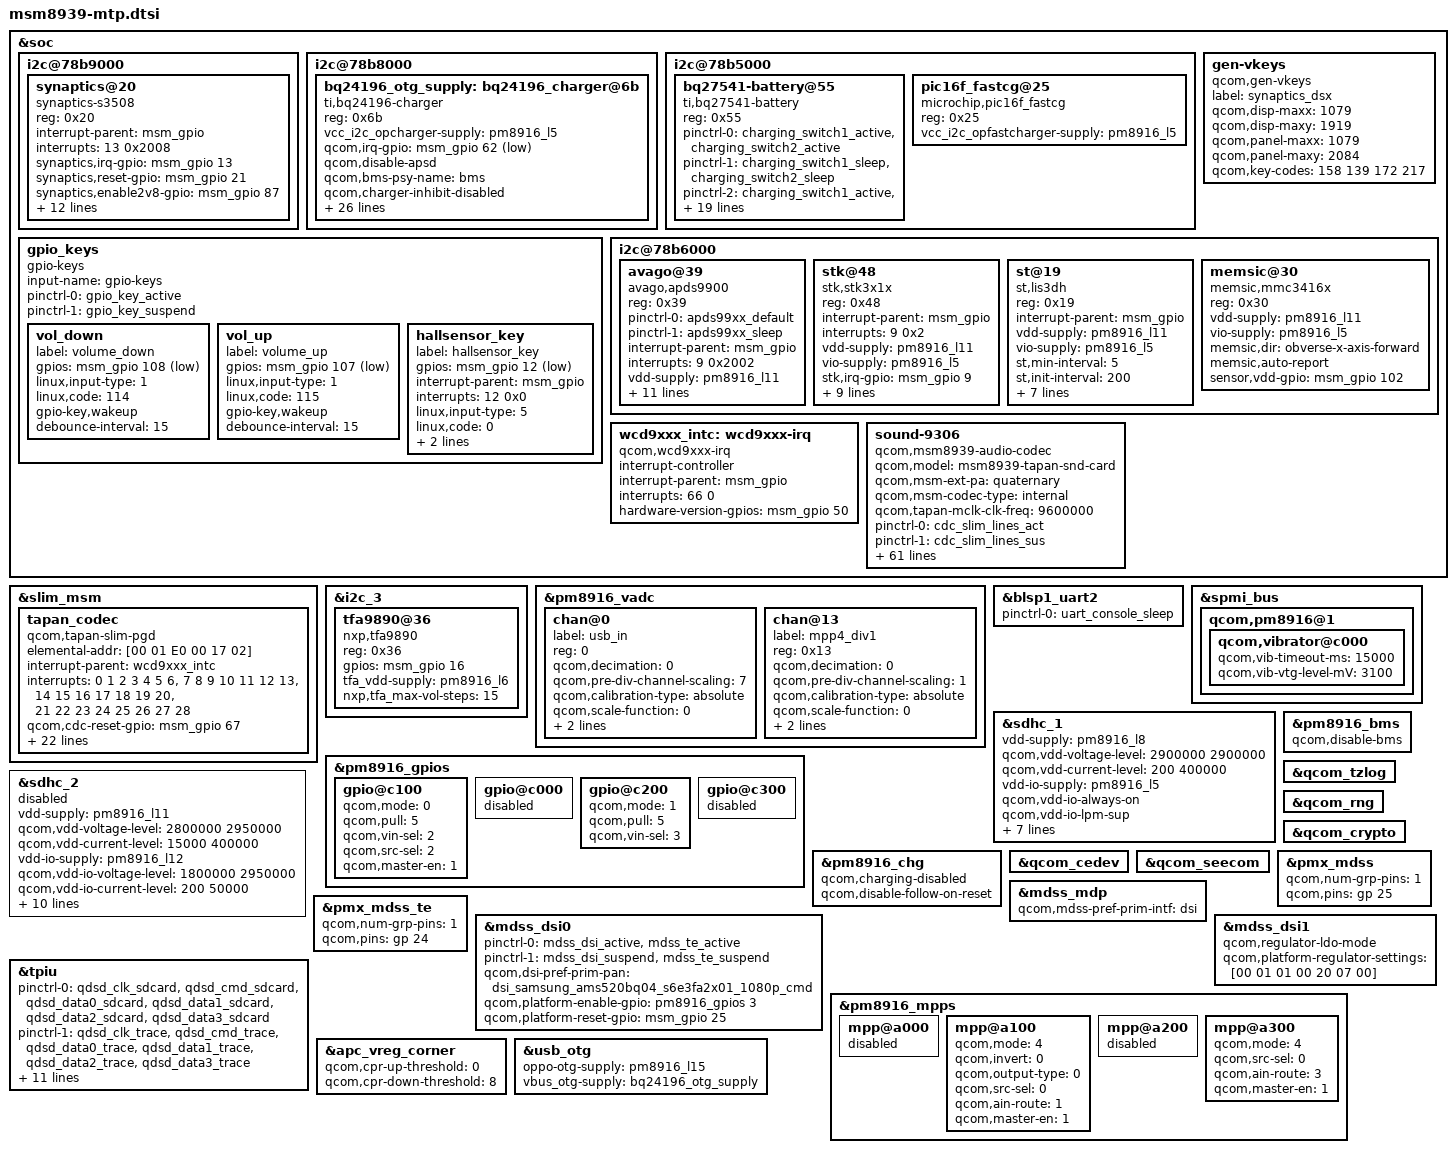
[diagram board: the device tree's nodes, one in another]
/* Copyright (c) 2014-2015, The Linux Foundation. All rights reserved.
 *
 * This program is free software; you can redistribute it and/or modify
 * it under the terms of the GNU General Public License version 2 and
 * only version 2 as published by the Free Software Foundation.
 *
 * This program is distributed in the hope that it will be useful,
 * but WITHOUT ANY WARRANTY; without even the implied warranty of
 * MERCHANTABILITY or FITNESS FOR A PARTICULAR PURPOSE.  See the
 * GNU General Public License for more details.
 */

#include "msm8939-pinctrl.dtsi"
#include "msm8939-camera-sensor-mtp.dtsi"

&soc {
	i2c@78b9000 { /* BLSP1 QUP5 */
		synaptics@20 {/*tong.han add for TP */
			compatible = "synaptics-s3508";
			reg = <0x20>;
			interrupt-parent = <&msm_gpio>;
			interrupts = <13 0x2008>;
			synaptics,irq-gpio = <&msm_gpio 13 0x2008>;
			synaptics,reset-gpio = <&msm_gpio 21 0x00>;
			synaptics,enable2v8-gpio = <&msm_gpio 87 0x00>;
			pinctrl-names = "default";
			pinctrl-0 = <&ts_int_active>;

			synaptics,max-num-support = <10>;
			synaptics,max-x-point = <10>;
			synaptics,button-map= <200 200 2021>;//width-height-y.position
			synaptics,tx-rx-num = <20 31>;
			synaptics,display-coords = <1080 1920>;
			synaptics,panel-coords = <0 0 1079 2084>;//max_x,max_y of display area--Not include virtual keys!
			synaptics,max-y-point = <1745>;
			vcc_i2c_1v8-supply = <&pm8916_l5>;
			/* huqiao@EXP.BasicDrv.Basic add for 15062 TP */
			//synaptics,glove-mode-enabled;
			synaptics,i2c-pull-up;
			synaptics,power-down;
			synaptics,disable-gpios;
		};
	};


	/*nanwei.Deng@bsp.drv add for charger start*/
	i2c@78b8000 { /* BLSP1 QUP4 =i2c4*/
		//Add bq24196_otg_supply for vbus_otg-supply by qiujianfeng
		bq24196_otg_supply: bq24196_charger@6b {
			status = "okay";
			compatible = "ti,bq24196-charger";
			reg = <0x6b>;

			vcc_i2c_opcharger-supply = <&pm8916_l5>;			/*Power source required to pull up i2c bus*/
			qcom,irq-gpio = <&msm_gpio 62 0x01>;					/*gpio STAT pin connects to.*/
			//qcom,fast_charger-gpio = <&msm_gpio 23 0x01>;			/*gpio fast_charger pin connects to.*/
			//qcom,usbphy_on-gpio = <&msm_gpio 38 0x01>;			/*gpio fast_charger pin connects to.*/
			//qcom,chg-valid-gpio= <&pm8941_gpios 0x02 0x01>;	/* */
			//qcom,charging-disabled;											/*This can then be overriden writing the the module parameter "charging_disabled"*/
			//qcom,chg-autonomous-mode;											/*it indicates that the charger is configured for autonomous operation*/
			qcom,disable-apsd;										/*APSD */
			qcom,bms-psy-name = "bms";									/*The main BMS device name */
			//qcom,iterm-disabled;
			qcom,charger-inhibit-disabled;							/* Charge Inhibit  */
			qcom,chg-vadc = <&pm8916_vadc>;							/* Corresponding VADC device's phandle.*/
			qcom,chg-adc_tm = <&pm8916_adc_tm>;						/* set recurring measurements and receive notification for batt_therm. */

			qcom,iterm-ma = <150>;									/*Charge termination current*/  //*chaoying.chen@EXP.BaseDrv.charge,2015/06/11  modify for charge v2.6 */
			qcom,recharge-mv = <100>;									/* The minimum voltage drop for recharger*/
			qcom,fast-charger-project-sign= <1>;						/* fastcharger project sign*/
			qcom,fastchg-current-max-ma = <1500>;						/*Maximum fast charging current.*/
			qcom,input-current-max-ma = <1500>;						/*Maximum input current.*/
			qcom,float-voltage-mv = <4320>;							/* from constant current charging to constant voltage chargeing for voltage threshold*/

			qcom,hot_bat_decidegc = <550>;							/* hot battery temperature in decidegC = 55*/
			qcom,temp_hot_vfloat_mv = <4100>;							/* hot battery temperature cutoff voltage =4.1V (45~55)*/
			qcom,temp_hot_fastchg_current_ma = <1000>;				/* hot battery temperature fast current   =0.75A (45~55)*/ ///*chaoying.chen@EXP.BaseDrv.charge,2015/06/03  modify for charge v2.6 */

			qcom,warm_bat_decidegc = <490>;							/* Warm battery temperature in decidegC= 45*/
			qcom,temp_warm_vfloat_mv = <4320>;						/* warn battery temperature cutoff voltage =4.1V (5~45)*/
			qcom,temp_warm_fastchg_current_ma = <1500>;				/* warn battery temperature fast current   =0.75A (5~45)*/

			qcom,pre_normal_bat_decidegc = <150>;						/* pre_cool battery temperature in decidegC= 5*/
			qcom,temp_pre_normal_vfloat_mv = <4320>;						/* warn battery temperature cutoff voltage =4.1V (5~45)*/
			qcom,temp_pre_normal_fastchg_current_ma = <1000>;				/* warn battery temperature fast current   =0.75A (5~45)*/ ///*chaoying.chen@EXP.BaseDrv.charge,2015/06/03  modify for charge v2.6 */

			qcom,pre_cool_bat_decidegc = <100>;						/* pre_cool battery temperature in decidegC= 5*/
			qcom,temp_pre_cool_vfloat_mv = <4200>;					/* pre_cool battery temperature cutoff voltage =4.2V (0~5)*/
			qcom,temp_pre_cool_fastchg_current_ma = <600>;		/* pre_cool battery temperature fast current   =0.75A (0~5)*/  ///*chaoying.chen@EXP.BaseDrv.charge,2015/06/03  modify for charge v2.6 */

			qcom,cool_bat_decidegc = <0>;							/* cold battery temperature in decidegC= -10*/
			qcom,temp_cool_vfloat_mv = <4000>;						/* cool battery temperature cutoff voltage =4.0V (-10~0) */
			qcom,temp_cool_fastchg_current_ma = <300>;				/* cool battery temperature fast current   =0.25A(-10~0)*/

			qcom,cold_bat_decidegc = <100>;							/* cold battery temperature in decidegC= -10*/
			qcom,bat_present_decidegc = <200>;						/* battery decidegc temperature in decidegC= -20*/
			//qcom,non_standard_vfloat_mv = <4000>;
			//qcom,non_standard_fastchg_current_ma = <512>;

			//Modify regulator name by qiujianfeng
			regulator-name = "bq24196_otg_vreg";
		};

	};
	i2c@78b5000 { /* BLSP1 QUP1 */
		bq27541-battery@55 {
			status = "okay";
			compatible = "ti,bq27541-battery";
			reg = <0x55>;

			pinctrl-names =   "switch1_act_switch2_act", "switch1_sleep_switch2_sleep",
							"switch1_act_switch3_act", "switch1_sleep_switch3_sleep",
							"switch1_act_switch2_sleep", "switch1_sleep_switch2_act",
							"clock_active","clock_sleep",
							"data_active","data_sleep",
							"reset_active","reset_sleep";
			pinctrl-0 = <&charging_switch1_active &charging_switch2_active >;
			pinctrl-1 = <&charging_switch1_sleep &charging_switch2_sleep >;
			pinctrl-2 = <&charging_switch1_active &charging_switch3_active >;
			pinctrl-3 = <&charging_switch1_sleep &charging_switch3_sleep >;
			pinctrl-4 = <&charging_switch1_active &charging_switch2_sleep >;
			pinctrl-5 = <&charging_switch1_sleep &charging_switch2_active >;
			pinctrl-6 = <&charging_clock_active >;
			pinctrl-7 = <&charging_clock_sleep >;
			pinctrl-8 = <&charging_data_active >;
			pinctrl-9 = <&charging_data_sleep >;
			pinctrl-10 = <&charging_reset_active >;
			pinctrl-11 = <&charging_reset_sleep >;

			qcom,charging_swtich1-gpio		= <&msm_gpio 23 0x00>;
			qcom,charging_swtich2-gpio		= <&msm_gpio 113 0x00>;
			qcom,charging_swtich3-gpio		= <&msm_gpio 38 0x00>;

			qcom,charging_reset-gpio			= <&msm_gpio 22 0x00>;
			qcom,charging_clock-gpio			= <&msm_gpio 115 0x00>;
			qcom,charging_data-gpio				= <&msm_gpio 109 0x00>;
		};
		pic16f_fastcg@25{
			status = "okay";
			compatible = "microchip,pic16f_fastcg";
			reg = <0x25>;

			vcc_i2c_opfastcharger-supply = <&pm8916_l5>;			/*Power source required to pull up i2c bus*/
		};
	};
	/*nanwei.Deng@bsp.drv add for charger end*/

	gen-vkeys {
		compatible = "qcom,gen-vkeys";
		label = "synaptics_dsx";
		qcom,disp-maxx = <1079>;
		qcom,disp-maxy = <1919>;
		qcom,panel-maxx = <1079>;
		qcom,panel-maxy = <2084>;
		qcom,key-codes = <158 139 172 217>;
	};

	gpio_keys {
		compatible = "gpio-keys";
		input-name = "gpio-keys";
		pinctrl-names = "tlmm_gpio_key_active","tlmm_gpio_key_suspend";
		pinctrl-0 = <&gpio_key_active>;
		pinctrl-1 = <&gpio_key_suspend>;
		vol_down {
			label = "volume_down";
			gpios = <&msm_gpio 108 0x1>;
			linux,input-type = <1>;
			linux,code = <114>;
			gpio-key,wakeup;
			debounce-interval = <15>;
		};
		vol_up {
			label = "volume_up";
			gpios = <&msm_gpio 107 0x1>;
			linux,input-type = <1>;
			linux,code = <115>;
			gpio-key,wakeup;
			debounce-interval = <15>;
		};
		/* LiuPing@Phone.BSP.Sensor, 2014/11/07, add for hall */
		hallsensor_key {
			label = "hallsensor_key";
			gpios = <&msm_gpio 12 1>;
			interrupt-parent = <&msm_gpio>;
			interrupts = <12 0x0>;
			linux,input-type = <5>;
			linux,code = <0>;
			gpio-key,wakeup;
			debounce-interval = <150>;
		};
	};

	i2c@78b6000 { /* BLSP1 QUP2 */
		/*#ifdef VENDOR_EDIT*/
		/* Xiaohua.tian@EXP.Driver.Sensor, 2015/06/03, modify light sensor. */
		/* Ambient light and proximity sensor */
		avago@39 {
			compatible = "avago,apds9900";
			reg = <0x39>;
			pinctrl-names = "default","sleep";
			pinctrl-0 = <&apds99xx_default>;
			pinctrl-1 = <&apds99xx_sleep>;
			interrupt-parent = <&msm_gpio>;
			interrupts = <9 0x2002>;
			vdd-supply = <&pm8916_l11>;
			vio-supply = <&pm8916_l5>;
			avago,irq-gpio = <&msm_gpio 9 0x2002>;
			avago,ps-threshold = <1023>;
			avago,ps-hysteresis-threshold = <1023>;
			avago,ps-pulse = <0x10>;
			avago,ps-pgain = <0>;
			avago,als-B = <223>;
			avago,als-C = <70>;
			avago,als-D = <142>;
			avago,ga-value = <48>;
			sensor,vdd-gpio = <&msm_gpio 102 0x00>;   /* set gpio to control ex-ldo for vdd supply in 14005. */
		};
		/*#endif*/

		/* LiuPing@Phone.BSP.Sensor, 2014/07/19, add for alsps:stk3x1x */
		stk@48 {
			compatible = "stk,stk3x1x";
			reg = <0x48>;
			interrupt-parent = <&msm_gpio>;
			interrupts = <9 0x2>;
			vdd-supply = <&pm8916_l17>;
			vio-supply = <&pm8916_l6>;
			stk,irq-gpio = <&msm_gpio 9 0x02>;
			stk,transmittance = <340>;
			stk,state-reg = <0x00>;
			stk,psctrl-reg = <0x31>;
			stk,alsctrl-reg = <0x3a>;
			stk,ledctrl-reg = <0x3F>;
			stk,wait-reg = <0x10>;
			stk,ps-thdh = <1400>;
			stk,ps-thdl = <1300>;
			//stk,use-fir;
		};

		/* LiuPing@Phone.BSP.Sensor, 2014/09/02, add for gsensor:lis3dh */
		st@19 { /* Accelerometer sensor */
			compatible = "st,lis3dh";
			reg = <0x19>;
			interrupt-parent = <&msm_gpio>;
			vdd-supply = <&pm8916_l11>;
			vio-supply = <&pm8916_l5>;
			st,min-interval = <5>;
			st,init-interval = <200>;
			st,axis-map-x = <0>;
			st,axis-map-y = <1>;
			st,axis-map-z = <2>;
			st,g-range = <2>;
			st,gpio-int1 = <&msm_gpio 34 0x2002>;
			st,negate-y;
			st,negate-z;
		};

		/* LiuPing@Phone.BSP.Sensor, 2014/09/04, add for msensor:mmc3416x */
		memsic@30 { /* Magnetic field sensor */
			compatible = "memsic,mmc3416x";
			reg = <0x30>;
			vdd-supply = <&pm8916_l11>;
			vio-supply = <&pm8916_l5>;
			memsic,dir = "obverse-x-axis-forward";
			memsic,auto-report;
			sensor,vdd-gpio = <&msm_gpio 102 0x00>;   /* set gpio to control ex-ldo for vdd supply in 14005. */
		};

		/* LiuPing@Phone.BSP.Sensor, 2014/07/19, add for alsps:stk3x1x */
		stk@48 {
			compatible = "stk,stk3x1x";
			reg = <0x48>;
			interrupt-parent = <&msm_gpio>;
			interrupts = <9 0x2>;
			vdd-supply = <&pm8916_l11>;
			vio-supply = <&pm8916_l5>;
			stk,irq-gpio = <&msm_gpio 9 0x02>;
			stk,transmittance = <340>;
			stk,state-reg = <0x00>;
			stk,psctrl-reg = <0x31>;
			stk,alsctrl-reg = <0x3a>;
			stk,ledctrl-reg = <0xFF>;
			stk,wait-reg = <0x07>;
			stk,ps-thdh = <1400>;
			stk,ps-thdl = <1300>;
			//stk,use-fir;
			sensor,vdd-gpio = <&msm_gpio 102 0x00>;   /* set gpio to control ex-ldo for vdd supply in 14005. */
		};
	};

/*OPPO 2014-08-28 zhzhyon Add for slim*/
  wcd9xxx_intc: wcd9xxx-irq {
    compatible = "qcom,wcd9xxx-irq";
		interrupt-controller;
		#interrupt-cells = <1>;
		interrupt-parent = <&msm_gpio>;
		interrupts = <66 0>;
		interrupt-names = "cdc-int";
		/*OPPO 2014-08-27 zhzhyon Add for compatible*/
		hardware-version-gpios = <&msm_gpio 50 0x00>;
		/*OPPO 2014-08-27 zhzhyon Add end*/		
	};
	
	/*OPPO 2014-08-25 zhzhyon Modify for slimbus and i2s*/
	sound-9306 {
		compatible = "qcom,msm8939-audio-codec";
		qcom,model = "msm8939-tapan-snd-card";
		qcom,msm-ext-pa = "quaternary";
 		qcom,msm-codec-type = "internal";
		qcom,tapan-mclk-clk-freq = <9600000>;
		pinctrl-names = "cdc_slim_lines_act", "cdc_slim_lines_sus",
				"cdc_lines_quat_ext_act", "cdc_lines_quat_ext_sus";
		pinctrl-0 = <&cdc_slim_lines_act>;
		pinctrl-1 = <&cdc_slim_lines_sus>;
		pinctrl-2 = <&cdc_slim_lines_act &ext_cdc_tlmm_lines_act>;
		pinctrl-3 = <&cdc_slim_lines_sus &ext_cdc_tlmm_lines_sus>;
		qcom,audio-routing =
			"RX_BIAS", "MCLK",
			"LDO_H", "MCLK",
			"SPK_OUT", "MCLK",
			"SPK_OUT", "EXT_VDD_SPKR",
			"AMIC1", "MIC BIAS1 External",
			"MIC BIAS1 External", "Handset Mic",
			"AMIC2", "MIC BIAS2 External",
			"MIC BIAS2 External", "Headset Mic",
			/*OPPO 2014-08-28 zhzhyon Add for reason*/
			"AMIC3", "MIC BIAS1 External",
			"MIC BIAS1 External", "Noise Mic",			
			/*OPPO 2014-08-28 zhzhyon Add end*/
			"AMIC4", "MIC BIAS2 External",
			"MIC BIAS2 External", "ANCRight Headset Mic",
			"AMIC5", "MIC BIAS2 External",
			"MIC BIAS2 External", "ANCLeft Headset Mic",
			"DMIC1", "MIC BIAS1 External",
			"MIC BIAS1 External", "Digital Mic1",
			"DMIC2", "MIC BIAS1 External",
			"MIC BIAS1 External", "Digital Mic2",
			"DMIC3", "MIC BIAS3 External",
			"MIC BIAS3 External", "Digital Mic3",
			"DMIC4", "MIC BIAS3 External",
			"MIC BIAS3 External", "Digital Mic4";
		/*OPPO 2014-07-21 zhzhyon Add for tfa9890 resource*/
		nxp,reset-gpio = <&msm_gpio 16 0x00>;
		audio-vdd-enable-gpios = <&msm_gpio 102 0x00>;
		spk-rec-sw-gpios = <&msm_gpio 97 0x00>;
		/*OPPO 2014-07-21 zhzhyon Add end*/
		/*OPPO 2014-08-26 zhzhyon Add for reason*/
		ap-audio-en-gpios = <&msm_gpio 69 0x00>;
		ap-lr-sel1-gpios = <&msm_gpio 23 0x00>;
		ap-lr-sel2-gpios = <&msm_gpio 38 0x00>;
		/*OPPO 2014-08-26 zhzhyon Add end*/
		/*OPPO 2014-08-26 zhzhyon Add for reason*/
		hs_det_compare-supply = <&pm8916_l11>;
		/*OPPO 2014-08-26 zhzhyon Add end*/
		/*OPPO 2014-09-18 zhzhyon Add for DVT tfa9890*/
		tfa9890_vdd-supply = <&pm8916_l6>;
		/*OPPO 2014-09-18 zhzhyon Add end*/

		asoc-platform = <&pcm0>, <&pcm1>, <&voip>, <&voice>,
				<&loopback>, <&compress>, <&hostless>,
				<&afe>, <&lsm>, <&routing>, <&lpa>;
		asoc-platform-names = "msm-pcm-dsp.0", "msm-pcm-dsp.1",
				"msm-voip-dsp", "msm-pcm-voice", "msm-pcm-loopback",
				"msm-compress-dsp", "msm-pcm-hostless", "msm-pcm-afe",
				"msm-lsm-client", "msm-pcm-routing", "msm-pcm-lpa";
		asoc-cpu = <&dai_hdmi>, <&dai_mi2s0>, <&dai_mi2s1>,
				<&dai_mi2s2>, <&dai_mi2s3>, <&sb_0_rx>, <&sb_0_tx>,
				<&sb_1_rx>, <&sb_1_tx>, <&sb_3_rx>, <&sb_3_tx>,
				<&sb_4_rx>, <&sb_4_tx>, <&sb_5_tx>, <&bt_sco_rx>,
				<&bt_sco_tx>, <&int_fm_rx>, <&int_fm_tx>, <&afe_pcm_rx>,
				<&afe_pcm_tx>, <&afe_proxy_rx>, <&afe_proxy_tx>,
				<&incall_record_rx>, <&incall_record_tx>, <&incall_music_rx>,
				<&incall_music_2_rx>;
		asoc-cpu-names = "msm-dai-q6-hdmi.8", "msm-dai-q6-mi2s.0",
				"msm-dai-q6-mi2s.1", "msm-dai-q6-mi2s.2",
				"msm-dai-q6-mi2s.3", "msm-dai-q6-dev.16384",
				"msm-dai-q6-dev.16385", "msm-dai-q6-dev.16386",
				"msm-dai-q6-dev.16387", "msm-dai-q6-dev.16390",
				"msm-dai-q6-dev.16391", "msm-dai-q6-dev.16392",
				"msm-dai-q6-dev.16393", "msm-dai-q6-dev.16395",
				"msm-dai-q6-dev.12288", "msm-dai-q6-dev.12289",
				"msm-dai-q6-dev.12292", "msm-dai-q6-dev.12293",
				"msm-dai-q6-dev.224", "msm-dai-q6-dev.225",
				"msm-dai-q6-dev.241", "msm-dai-q6-dev.240",
				"msm-dai-q6-dev.32771", "msm-dai-q6-dev.32772",
				"msm-dai-q6-dev.32773", "msm-dai-q6-dev.32770";
		asoc-codec = <&stub_codec>;
		asoc-codec-names = "msm-stub-codec.1";

 	};
	/*OPPO 2014-08-25 zhzhyon Modify end*/
};
/*OPPO 2014-08-28 zhzhyon Add end*/

/*OPPO 2014-08-23 zhzhyon Add for slim*/
&slim_msm {
	status = "ok";
	tapan_codec {
		compatible = "qcom,tapan-slim-pgd";
		elemental-addr = [00 01 E0 00 17 02];
		interrupt-parent = <&wcd9xxx_intc>;
		interrupts = <0 1 2 3 4 5 6>, <7 8 9 10 11 12 13>,
			     <14 15 16 17 18 19 20>, <21 22 23 24 25 26 27 28>;
		qcom,cdc-reset-gpio = <&msm_gpio 67 0>;
		qcom,cdc-micbias1-ext-cap;
		cdc-vdd-buck-supply = <&pm8916_s4>;
		qcom,cdc-vdd-buck-voltage = <1800000 2150000>;
		qcom,cdc-vdd-buck-current = <650000>;
		cdc-vdd-cx-supply = <&pm8916_l2>;
		qcom,cdc-vdd-cx-voltage = <1200000 1200000>;
		qcom,cdc-vdd-cx-current = <10000>;
		qcom,cdc-static-supplies = "cdc-vdd-cx";
		qcom,cdc-cp-supplies = "cdc-vdd-buck";
		qcom,cdc-micbias-ldoh-v = <0x3>;
		qcom,cdc-micbias-cfilt1-mv = <1800>;
		qcom,cdc-micbias-cfilt2-mv = <1800>;
		qcom,cdc-micbias-cfilt3-mv = <1800>;
		qcom,cdc-micbias1-cfilt-sel = <0x0>;
		qcom,cdc-micbias2-cfilt-sel = <0x1>;
		qcom,cdc-micbias3-cfilt-sel = <0x2>;
		qcom,cdc-micbias4-cfilt-sel = <0x2>;
		qcom,cdc-dmic-sample-rate = <4800000>;
		qcom,cdc-mclk-clk-rate = <9600000>;
		qcom,cdc-slim-ifd = "tapan-slim-ifd";
		qcom,cdc-slim-ifd-elemental-addr = [00 00 E0 00 17 02];
        };
 };

&i2c_3 {
	tfa9890@36 {
		compatible = "nxp,tfa9890";
		reg = <0x36>;
		gpios = <&msm_gpio 16 0x00>;   /* RESET */
		tfa_vdd-supply = <&pm8916_l6>;
		nxp,tfa_max-vol-steps = <15>;
	};
};

/*dengnw  add for  adc 2014-07-22 start*/
&pm8916_vadc {
	chan@0 {
		label = "usb_in";
		reg = <0>;
		qcom,decimation = <0>;
		qcom,pre-div-channel-scaling = <7>;
		qcom,calibration-type = "absolute";
		qcom,scale-function = <0>;
		qcom,hw-settle-time = <0>;
		qcom,fast-avg-setup = <0>;
	};
	chan@13 {
		label = "mpp4_div1";
		reg = <0x13>;
		qcom,decimation = <0>;
		qcom,pre-div-channel-scaling = <1>;
		qcom,calibration-type = "absolute";
		qcom,scale-function = <0>;
		qcom,hw-settle-time = <2>;
		qcom,fast-avg-setup = <0>;
	};
};
/*dengnw  add for  adc 2014-07-22 end*/

&blsp1_uart2 {
	status = "ok";
	pinctrl-names = "default";
	pinctrl-0 = <&uart_console_sleep>;
};

&pm8916_gpios {
	gpio@c100 { /* GPIO 2 */
		/* NFC_CLK_REQ */
		qcom,mode = <0>; /* QPNP_PIN_MODE_DIG_IN */
		qcom,pull = <5>; /* QPNP_PIN_PULL_NO */
		qcom,vin-sel = <2>; /* QPNP_PIN_VIN2 */
		qcom,src-sel = <2>; /* QPNP_PIN_SEL_FUNC_1 */
		qcom,master-en = <1>;
	};
};
&spmi_bus {
	qcom,pm8916@1 {
		qcom,vibrator@c000 {
			status = "okay";
			qcom,vib-timeout-ms = <15000>;
			qcom,vib-vtg-level-mV = <3100>;
		};
	};
};

&sdhc_1 {
	vdd-supply = <&pm8916_l8>;
	qcom,vdd-voltage-level = <2900000 2900000>;
	qcom,vdd-current-level = <200 400000>;

	vdd-io-supply = <&pm8916_l5>;
	qcom,vdd-io-always-on;
	qcom,vdd-io-lpm-sup;
	qcom,vdd-io-voltage-level = <1800000 1800000>;
	qcom,vdd-io-current-level = <200 60000>;

	pinctrl-names = "active", "sleep";
	pinctrl-0 = <&sdc1_clk_on &sdc1_cmd_on &sdc1_data_on>;
	pinctrl-1 = <&sdc1_clk_off &sdc1_cmd_off &sdc1_data_off>;

	qcom,nonremovable;

	status = "ok";
};

&sdhc_2 {
	vdd-supply = <&pm8916_l11>;
	qcom,vdd-voltage-level = <2800000 2950000>;
	qcom,vdd-current-level = <15000 400000>;

	vdd-io-supply = <&pm8916_l12>;
	qcom,vdd-io-voltage-level = <1800000 2950000>;
	qcom,vdd-io-current-level = <200 50000>;

	pinctrl-names = "active", "sleep";
	pinctrl-0 = <&sdc2_clk_on &sdc2_cmd_on &sdc2_data_on &sdc2_cd_on>;
	pinctrl-1 = <&sdc2_clk_off &sdc2_cmd_off &sdc2_data_off &sdc2_cd_off>;

	#address-cells = <0>;
	interrupt-parent = <&sdhc_2>;
	interrupts = <0 1 2>;
	#interrupt-cells = <1>;
	interrupt-map-mask = <0xffffffff>;
	interrupt-map = <0 &intc 0 125 0
			1 &intc 0 221 0
			2 &msm_gpio 38 0>;
	interrupt-names = "hc_irq", "pwr_irq", "status_irq";
	cd-gpios = <&msm_gpio 38 0x1>;

	status = "disabled";
};

&pm8916_chg {
	status = "ok";
	qcom,charging-disabled;
	/*dengnw@bsp.drv  add for  adc 2014-07-22 end*/
	qcom,disable-follow-on-reset;
};

&pm8916_bms {
	status = "ok";
	qcom,disable-bms;
};

&qcom_tzlog {
	status = "okay";
};

&qcom_rng {
	status = "okay";
};

&qcom_crypto {
	status = "okay";
};

&qcom_cedev {
	status = "okay";
};

&qcom_seecom {
	status = "okay";
};

&mdss_mdp {
	qcom,mdss-pref-prim-intf = "dsi";
};

&pmx_mdss {
	qcom,num-grp-pins = <1>;
	/*#ifdef VENDOR_EDIT yxr delete*/
	/*qcom,pins = <&gp 97>, <&gp 25>, <&gp 98>;*/
	qcom,pins = <&gp 25>;
};

&pmx_mdss_te {
	qcom,num-grp-pins = <1>;
	qcom,pins = <&gp 24>;
};

#include "dsi-panel-samsung_ams520bq04_s6e3fa2x01_1080p_cmd.dtsi"
&mdss_dsi0 {
	pinctrl-names = "mdss_default", "mdss_sleep";
	pinctrl-0 = <&mdss_dsi_active &mdss_te_active>;
	pinctrl-1 = <&mdss_dsi_suspend &mdss_te_suspend>;

	qcom,dsi-pref-prim-pan = <&dsi_samsung_ams520bq04_s6e3fa2x01_1080p_cmd>;

	qcom,platform-enable-gpio = <&pm8916_gpios 3 0>;
	qcom,platform-reset-gpio = <&msm_gpio 25 0>;
	/*qcom,platform-te-gpio = <&msm_gpio 24 0>;
	qcom,platform-bklight-en-gpio = <&msm_gpio 98 0>;*/
};

&mdss_dsi1 {
	qcom,regulator-ldo-mode;
	qcom,platform-regulator-settings = [00 01 01 00 20 07 00];
};

&pm8916_mpps {
	mpp@a000 { /* MPP 1 */
		/* VDD_PX */
		status = "disabled";
	};

	mpp@a100 { //MPP2
		status = "ok";
		qcom,mode = <4>; // AIN input
		qcom,invert = <0>; //No Invert
		qcom,output-type = <0>; //CMOS
		qcom,src-sel = <0>; //MPP Constant
		qcom,ain-route = <1>; // QPNP_PIN_AIN_AMUX_CH6 = 1 for MPP2
		qcom,master-en = <1>; // Function constant
	};

	mpp@a200 { /* MPP 3 */
		/* VREF DAC */
		status = "disabled";
	};
	/*dengnw add for MPP4 to adc 2014-07-22 start*/
/*
	mpp@a300 { // MPP 4 //
		// Backlight PWM //
		qcom,mode = <1>;		// Digital output //
		qcom,invert = <0>;		//Disable invert //
		qcom,src-sel = <4>;		//DTEST1 //
		qcom,vin-sel = <0>;		// VPH_PWR //
		qcom,master-en = <1>;		// Enable MPP //
	};
*/
	mpp@a300 { /* MPP 4 */
		// adc   //
		qcom,mode = <4>; // QPNP_PIN_MODE_AIN
		qcom,src-sel = <0>; // QPNP_PIN_SEL_FUNC_CONSTANT
		qcom,ain-route = <3>; // QPNP_PIN_AIN_AMUX_CH8
		qcom,master-en = <1>; // Enable features
	};
	/*dengnw add for MPP4 to adc 2014-07-22 end*/
};

&pm8916_gpios {
	gpio@c000 { /* GPIO 1 */
		/* Battery UICC Alarm */
		status = "disabled";
	};

	gpio@c100 { /* GPIO 2 */
		/* NFC_CLK_REQ */
		qcom,mode = <0>; /* QPNP_PIN_MODE_DIG_IN */
		qcom,pull = <5>; /* QPNP_PIN_PULL_NO */
		qcom,vin-sel = <2>; /* QPNP_PIN_VIN2 */
		qcom,src-sel = <2>; /* QPNP_PIN_SEL_FUNC_1 */
		qcom,master-en = <1>;
	};
	/*#ifdef VENDOR_EDIT Xiaori.Yuan modified for lcd*/
	gpio@c200 { /* GPIO 3 */
		/* External regulator control for WTR */
		/*status = "disabled";*/
		status = "ok";
		qcom,mode = <1>; /* QPNP_PIN_MODE_DIG_OUT */
		qcom,pull = <5>; /* QPNP_PIN_PULL_NO */
		qcom,vin-sel = <3>; /* QPNP_PIN_VIN3 */
		/*qcom,src-sel = <2>;  QPNP_PIN_SEL_FUNC_1 */
		/*qcom,master-en = <1>;*/
	};

	gpio@c300 { /* GPIO 4 */
		/* External regulator control for APC */
		status = "disabled";
	};
};

/* CoreSight */
&tpiu {
	pinctrl-names = "sdcard", "trace", "swduart",
			"swdtrc", "jtag", "spmi";
	/* NIDnT */
	pinctrl-0 = <&qdsd_clk_sdcard &qdsd_cmd_sdcard
		     &qdsd_data0_sdcard &qdsd_data1_sdcard
		     &qdsd_data2_sdcard &qdsd_data3_sdcard>;
	pinctrl-1 = <&qdsd_clk_trace &qdsd_cmd_trace
		     &qdsd_data0_trace &qdsd_data1_trace
		     &qdsd_data2_trace &qdsd_data3_trace>;
	pinctrl-2 = <&qdsd_cmd_swduart &qdsd_data0_swduart
		     &qdsd_data1_swduart &qdsd_data2_swduart
		     &qdsd_data3_swduart>;
	pinctrl-3 = <&qdsd_clk_swdtrc &qdsd_cmd_swdtrc
		     &qdsd_data0_swdtrc &qdsd_data1_swdtrc
		     &qdsd_data2_swdtrc &qdsd_data3_swdtrc>;
	pinctrl-4 = <&qdsd_cmd_jtag &qdsd_data0_jtag
		     &qdsd_data1_jtag &qdsd_data2_jtag
		     &qdsd_data3_jtag>;
	pinctrl-5 = <&qdsd_clk_spmi &qdsd_cmd_spmi
		     &qdsd_data0_spmi &qdsd_data3_spmi>;
};

&apc_vreg_corner {
		qcom,cpr-up-threshold = <0>;
		qcom,cpr-down-threshold = <8>;
};

&usb_otg {
    //qcom,hsusb-otg-mode = <3>;
    oppo-otg-supply = <&pm8916_l15>;
    vbus_otg-supply = <&bq24196_otg_supply>;
};
